# CY8C5267LTI_LP089 register map
File version: 0.1
CY8C52LP
Registers are 8-bit, read-write, no defined reset value unless marked. A register's access mark holds for its fields unless they carry their own. Offsets are from the block's base; lines under a group give offsets from that group; [hi:lo] are bit positions; {n}, {i} and the like mark numbered series; 'fields as' and 'values as' point back to an identical list; <NAME> marks a mode.

## Memory map
0x00000000 FltrReg
0x00000000 Pulse_50us
0x00000000 EZI2Cs
0x00000000 UART_READER — UART
0x00000000 OSDPReaderTimer
0x00000000 Status_Reg_HwPort
0x00000000 USBUART — USBFS
0x00000000 I2C_Master
0x00000000 SleepTimer
0x00000000 UART_ACS — UART
0x00000000 UART_TIMER
0x00000000 UART_1 — UART
0x00000000 Timeout_Timer
0x00000000 FilterReg
0x00000000 OptSelect
0x00000000 Tamper_Timer

## FltrReg
Base 0x00000000
0x40006568 FltrReg_STATUS_REG
0x40006588 FltrReg_MASK_REG
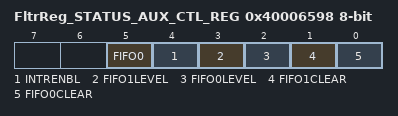
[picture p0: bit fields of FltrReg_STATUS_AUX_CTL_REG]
0x40006598 FltrReg_STATUS_AUX_CTL_REG
  [5] FIFO0 — FIFO0 clear
    1=ENABLED (Enable counter); 0=DISABLED (Disable counter)
  [4] INTRENBL — Enables or disables the Interrupt
    1=ENABLED (Interrupt enabled); 0=DISABLED (Interrupt disabled)
  [3] FIFO1LEVEL — FIFO level
    1=ENABLED (FIFO LVL: input mode: FIFO at least 1/2 empty; output mode: FIFO at least 1/2 full); 0=DISABLED (FIFO LVL: input mode: FIFO not full; output mode: FIFO not empty)
  [2] FIFO0LEVEL — FIFO level
    values as FIFO1LEVEL
  [1] FIFO1CLEAR — FIFO clear
    1=ENABLED (Clear FIFO state); 0=DISABLED (Normal FIFO operation)
  [0] FIFO0CLEAR — FIFO clear
    values as FIFO1CLEAR

## Pulse_50us
Base 0x00000000
0x4000650A Pulse_50us_COUNTER — UDB.A0 - Current Down Counter Value
0x4000652A Pulse_50us_PERIOD — UDB.D0 - Assigned Period
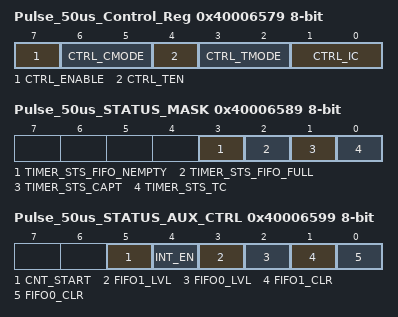
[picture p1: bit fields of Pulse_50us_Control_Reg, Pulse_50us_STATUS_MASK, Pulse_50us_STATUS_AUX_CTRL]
0x40006579 Pulse_50us_Control_Reg — UDB Control Register - Assigned Control Register Value
  [7] CTRL_ENABLE — Enable the Timer
  [6:5] CTRL_CMODE — Capture Mode
  [4] CTRL_TEN — Trigger Enable Bit
  [3:2] CTRL_TMODE — Trigger Mode
  [1:0] CTRL_IC — Interrupt Count
0x40006589 Pulse_50us_STATUS_MASK — UDB Status bits Interrupt Mask Enable Register
  [3] TIMER_STS_FIFO_NEMPTY ro — FIFO Empty status
  [2] TIMER_STS_FIFO_FULL ro — FIFO Full Status
  [1] TIMER_STS_CAPT ro — Enables the Interrupt on Capture
  [0] TIMER_STS_TC ro — Enables the Interrupt on TC
0x40006599 Pulse_50us_STATUS_AUX_CTRL — UDB Auxilliary Control Register
  [5] CNT_START — FIFO0 clear
    0=E_CNT_START0 (Disable counter); 1=E_CNT_START1 (Enable counter)
  [4] INT_EN
    0=E_INT_EN0 (Interrupt disabled); 1=E_INT_EN1 (Interrupt enabled)
  [3] FIFO1_LVL — FIFO level
    0=E_FIFO_LVL_0 (FIFO LVL: input mode: FIFO not full; output mode: FIFO not empty); 1=E_FIFO_LVL_1 (FIFO LVL: input mode: FIFO at least 1/2 empty; output mode: FIFO at least 1/2 full)
  [2] FIFO0_LVL — FIFO level
    values as FIFO1_LVL
  [1] FIFO1_CLR — FIFO1 clear
    0=E_FIFO_CLR_0 (Normal FIFO operation); 1=E_FIFO_CLR_1 (Clear FIFO state)
  [0] FIFO0_CLR — FIFO0 clear
    values as FIFO1_CLR

## UART_READER — UART
Base 0x00000000
0x40006528 HD_UART_READER_RX_ADDRESS1 — RX Address1 Register
0x40006538 HD_UART_READER_RX_ADDRESS2 — RX Address2 Register
0x40006548 HD_UART_READER_RX_DATA — RX Data Register
0x40006558 HD_UART_READER_TX_DATA — TX Data Register
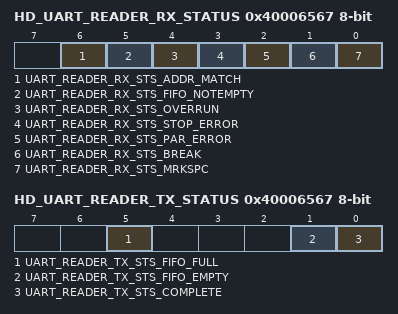
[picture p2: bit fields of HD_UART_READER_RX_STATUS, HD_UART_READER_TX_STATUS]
0x40006567 HD_UART_READER_RX_STATUS — RX status register
  [6] UART_READER_RX_STS_ADDR_MATCH ro, [5] UART_READER_RX_STS_FIFO_NOTEMPTY ro, [4] UART_READER_RX_STS_OVERRUN ro, [3] UART_READER_RX_STS_STOP_ERROR ro, [2] UART_READER_RX_STS_PAR_ERROR ro, [1] UART_READER_RX_STS_BREAK ro, [0] UART_READER_RX_STS_MRKSPC ro
0x40006567 HD_UART_READER_TX_STATUS — TX status register
  [5] UART_READER_TX_STS_FIFO_FULL ro, [1] UART_READER_TX_STS_FIFO_EMPTY ro, [0] UART_READER_TX_STS_COMPLETE ro

## OSDPReaderTimer
Base 0x00000000
0x40006400 OSDPReaderTimer_COUNTER 16-bit — UDB.A0 - Current Down Counter Value
0x40006420 OSDPReaderTimer_PERIOD 16-bit — UDB.D0 - Assigned Period
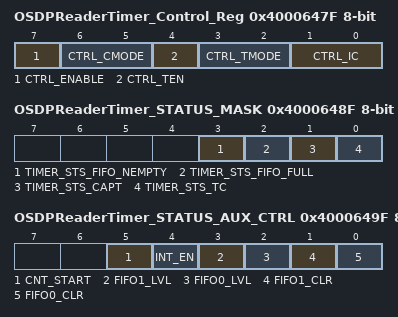
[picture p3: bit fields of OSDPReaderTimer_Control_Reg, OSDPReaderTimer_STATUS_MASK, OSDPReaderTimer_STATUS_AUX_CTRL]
0x4000647F OSDPReaderTimer_Control_Reg — UDB Control Register - Assigned Control Register Value
  [7] CTRL_ENABLE — Enable the Timer
  [6:5] CTRL_CMODE — Capture Mode
  [4] CTRL_TEN — Trigger Enable Bit
  [3:2] CTRL_TMODE — Trigger Mode
  [1:0] CTRL_IC — Interrupt Count
0x4000648F OSDPReaderTimer_STATUS_MASK — UDB Status bits Interrupt Mask Enable Register
  [3] TIMER_STS_FIFO_NEMPTY ro — FIFO Empty status
  [2] TIMER_STS_FIFO_FULL ro — FIFO Full Status
  [1] TIMER_STS_CAPT ro — Enables the Interrupt on Capture
  [0] TIMER_STS_TC ro — Enables the Interrupt on TC
0x4000649F OSDPReaderTimer_STATUS_AUX_CTRL — UDB Auxilliary Control Register
  [5] CNT_START — FIFO0 clear
    0=E_CNT_START0 (Disable counter); 1=E_CNT_START1 (Enable counter)
  [4] INT_EN
    0=E_INT_EN0 (Interrupt disabled); 1=E_INT_EN1 (Interrupt enabled)
  [3] FIFO1_LVL — FIFO level
    0=E_FIFO_LVL_0 (FIFO LVL: input mode: FIFO not full; output mode: FIFO not empty); 1=E_FIFO_LVL_1 (FIFO LVL: input mode: FIFO at least 1/2 empty; output mode: FIFO at least 1/2 full)
  [2] FIFO0_LVL — FIFO level
    values as FIFO1_LVL
  [1] FIFO1_CLR — FIFO1 clear
    0=E_FIFO_CLR_0 (Normal FIFO operation); 1=E_FIFO_CLR_1 (Clear FIFO state)
  [0] FIFO0_CLR — FIFO0 clear
    values as FIFO1_CLR
